# ESM_AM62A_MAIN0_CFG register map
Vendor: Texas Instruments
Peripheral module from a debugger description file (folder am62A).
Registers are 32-bit, read-only, reset 0x0 unless marked. A register's access mark holds for its fields unless they carry their own. Offsets are as the file gives them; lines under a group give offsets from that group; [hi:lo] are bit positions; {n}, {i} and the like mark numbered series; 'fields as' and 'values as' point back to an identical list; <NAME> marks a mode.

## ESM_AM62A_MAIN0_CFG
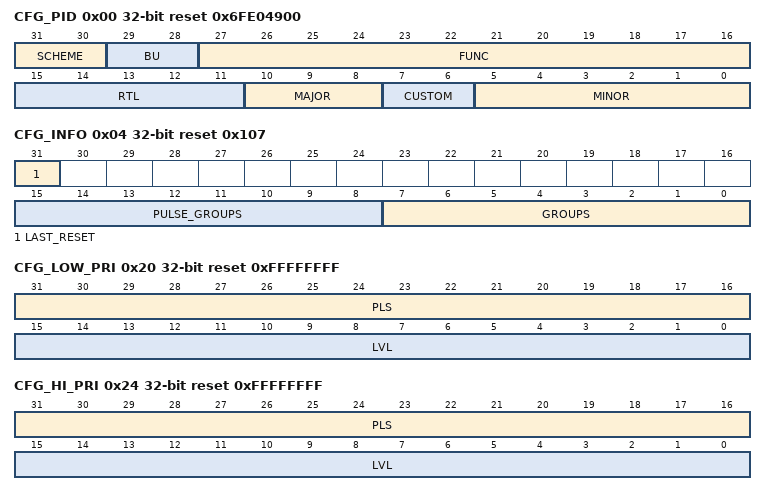
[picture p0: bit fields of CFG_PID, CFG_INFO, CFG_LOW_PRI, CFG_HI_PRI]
0x00 CFG_PID reset 0x6FE04900
  [31:30] SCHEME — PID register scheme
  [29:28] BU — Business Unit: 10 = Processors
  [27:16] FUNC — Module ID
  [15:11] RTL — RTL revision. Will vary depending on release.
  [10:8] MAJOR — Major revision
  [7:6] CUSTOM
  [5:0] MINOR — Minor revision
0x00 CFG_RAW access not given
  [31:0] STS — This is the raw status/set for errors Group A (access R/W1TS)
0x04 CFG_INFO reset 0x107
  [31] LAST_RESET — Indicates the Source of the last Reset
  [15:8] PULSE_GROUPS — Number of Pulse Error Groups
  [7:0] GROUPS — Total number of Error Groups
0x04 CFG_STS access not given
  [31:0] MSK — This is the masked status/clear for errors in Group A (access R/W1TC)
0x08 CFG_EN rw
  [3:0] KEY — Global Enable
0x08 CFG_INTR_EN_SET access not given
  [31:0] MSK — This is the mask enable set for errors in Group A (access R/W1TS)
0x0C CFG_SFT_RST wo
  [3:0] KEY — Global Soft Reset
0x0C CFG_INTR_EN_CLR access not given
  [31:0] MSK — This is the mask enable clear for errors in Group A (access R/W1TC)
0x10 CFG_ERR_RAW access not given
  [6:0] STS — This is the raw status for config errors (access R/W1TS)
0x10 CFG_INT_PRIO rw
  [31:0] MSK — This is interrupt priority for errors in Group A
0x14 CFG_ERR_STS access not given
  [6:0] MSK — This is the masked status/clear for config errors (access R/W1TC)
0x14 CFG_PIN_EN_SET access not given
  [31:0] MSK — This is the error pin influence enable set for errors in Group A (access R/W1TS)
0x18 CFG_ERR_EN_SET access not given
  [6:0] MSK — This is the mask enable set for config errors (access R/W1TS)
0x18 CFG_PIN_EN_CLR access not given
  [31:0] MSK — This is the error pin influence enable clear for errors in Group A (access R/W1TC)
0x1C CFG_ERR_EN_CLR access not given
  [6:0] MSK — This is the mask enable clear for config errors (access R/W1TC)
0x20 CFG_LOW_PRI reset 0xFFFFFFFF
  [31:16] PLS — This is the highest priority outstanding low priority pulse interrupt
  [15:0] LVL — This is the highest priority outstanding low priority level interrupt
0x24 CFG_HI_PRI reset 0xFFFFFFFF
  [31:16] PLS — This is the highest priority outstanding high priority pulse interrupt
  [15:0] LVL — This is the highest priority outstanding high priority level interrupt
0x28 CFG_LOW
  [31:0] STS — This is the raw status for config errors
0x2C CFG_HI
  [31:0] STS — This is the raw status for config errors
0x30 CFG_EOI wo
  [10:0] KEY — This is the interrupt being serviced
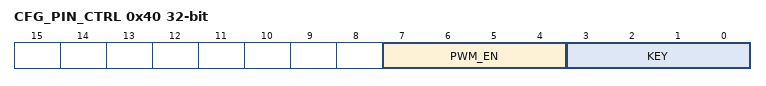
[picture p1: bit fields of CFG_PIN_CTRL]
0x40 CFG_PIN_CTRL rw
  [7:4] PWM_EN — PWM enable
  [3:0] KEY — Pin Control Key
0x44 CFG_PIN_STS
  [0] VAL — Value of the error_pin_n
0x48 CFG_PIN_CNTR
  [23:0] COUNT — Current Counter Value
0x4C CFG_PIN_CNTR_PRE rw
  [23:0] COUNT — Counter Pre-Load Value
0x50 CFG_PWMH_PIN_CNTR
  [23:0] COUNT — Current Counter Value
0x54 CFG_PWMH_PIN_CNTR_PRE rw
  [23:0] COUNT — Counter Pre-Load Value
0x58 CFG_PWML_PIN_CNTR
  [23:0] COUNT — Current Counter Value
0x5C CFG_PWML_PIN_CNTR_PRE rw
  [23:0] COUNT — Counter Pre-Load Value
